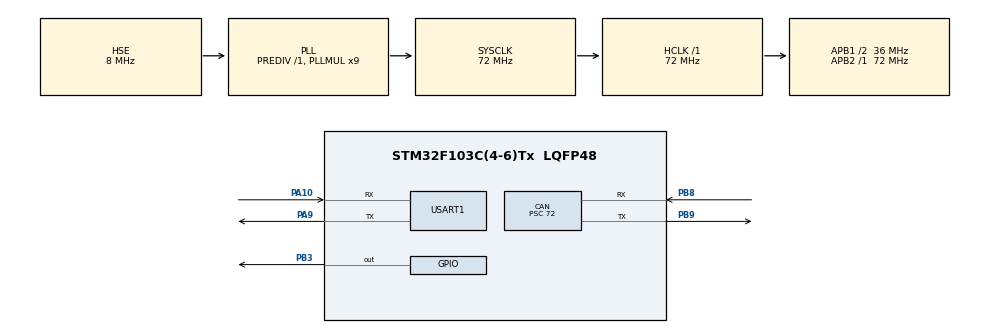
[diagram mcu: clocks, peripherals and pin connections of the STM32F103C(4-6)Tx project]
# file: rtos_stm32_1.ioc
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CAN.BS1=CAN_BS1_2TQ
CAN.CalculateBaudRate=125000
CAN.CalculateTimeBit=8000
CAN.CalculateTimeQuantum=2000.0
CAN.Prescaler=72
FREERTOS.Tasks01=uartTask,0,128,Task_UART_Receive,Default,NULL,Dynamic,NULL,NULL;canTask,0,128,Task_CAN_Send,Default,NULL,Dynamic,NULL,NULL;relay1Task,0,128,Task_Relay1_Control,Default,NULL,Dynamic,NULL,NULL
FREERTOS.configUSE_NEWLIB_REENTRANT=1
Mcu.Family=STM32F1
Mcu.Name=STM32F103C(4-6)Tx
Mcu.Package=LQFP48
NVIC.CAN1_RX1_IRQn=true\:5\:0\:false\:false\:true\:true\:true\:true\:true
NVIC.PriorityGroup=NVIC_PRIORITYGROUP_4
NVIC.TIM3_IRQn=true\:15\:0\:false\:false\:true\:false\:false\:true\:true
NVIC.TimeBase=TIM3_IRQn
NVIC.TimeBaseIP=TIM3
PA10.Mode=Asynchronous
PA10.Signal=USART1_RX
PA13.Mode=Serial_Wire
PA13.Signal=SYS_JTMS-SWDIO
PA14.Mode=Serial_Wire
PA14.Signal=SYS_JTCK-SWCLK
PA9.Mode=Asynchronous
PA9.Signal=USART1_TX
PB3.Signal=GPIO_Output
PB8.Mode=CAN_Activate
PB8.Signal=CAN_RX
PB9.Mode=CAN_Activate
PB9.Signal=CAN_TX
PD0-OSC_IN.Mode=HSE-External-Oscillator
PD0-OSC_IN.Signal=RCC_OSC_IN
PD1-OSC_OUT.Mode=HSE-External-Oscillator
PD1-OSC_OUT.Signal=RCC_OSC_OUT
ProjectManager.HeapSize=0x200
ProjectManager.StackSize=0x400
ProjectManager.TargetToolchain=STM32CubeIDE
RCC.AHBFreq_Value=72000000
RCC.APB1CLKDivider=RCC_HCLK_DIV2
RCC.APB1Freq_Value=36000000
RCC.APB1TimFreq_Value=72000000
RCC.APB2Freq_Value=72000000
RCC.APB2TimFreq_Value=72000000
RCC.HCLKFreq_Value=72000000
RCC.PLLMUL=RCC_PLL_MUL9
RCC.PLLSourceVirtual=RCC_PLLSOURCE_HSE
RCC.SYSCLKFreq_VALUE=72000000
RCC.SYSCLKSource=RCC_SYSCLKSOURCE_PLLCLK
RCC.USBFreq_Value=72000000
USART1.VirtualMode=VM_ASYNC
VP_FREERTOS_VS_CMSIS_V1.Mode=CMSIS_V1
VP_SYS_VS_tim3.Mode=TIM3
board=custom

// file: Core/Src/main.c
/* USER CODE BEGIN Header */
/**
  ******************************************************************************
  * @file           : main.c
  * @brief          : Main program body
  ******************************************************************************
  * @attention
  *
  * Copyright (c) 2025 STMicroelectronics.
  * All rights reserved.
  *
  * This software is licensed under terms that can be found in the LICENSE file
  * in the root directory of this software component.
  * If no LICENSE file comes with this software, it is provided AS-IS.
  *
  ******************************************************************************
  */
/* USER CODE END Header */
#include "main.h"
#include "cmsis_os.h"
#include <string.h>

CAN_HandleTypeDef hcan;

UART_HandleTypeDef huart1;

osThreadId uartTaskHandle;
osThreadId canTaskHandle;
osThreadId relay1TaskHandle;
QueueHandle_t uartQueue, canQueue;

void SystemClock_Config(void);
static void MX_GPIO_Init(void);
static void MX_CAN_Init(void);
static void MX_USART1_UART_Init(void);
void Task_UART_Receive(void const * argument);
void Task_CAN_Send(void const * argument);
void Task_Relay1_Control(void const * argument);

int main(void)
{

  /* MCU Configuration--------------------------------------------------------*/

  /* Reset of all peripherals, Initializes the Flash interface and the Systick. */
  HAL_Init();

  /* Configure the system clock */
  SystemClock_Config();

  /* Initialize all configured peripherals */
  MX_GPIO_Init();
  MX_CAN_Init();
  MX_USART1_UART_Init();
  /* USER CODE BEGIN 2 */
  HAL_GPIO_WritePin(GPIOB, GPIO_PIN_3, GPIO_PIN_SET);
  uartQueue = xQueueCreate(10, sizeof(uint8_t));
        canQueue = xQueueCreate(10, sizeof(uint8_t));
  /* USER CODE END 2 */

  /* Create the thread(s) */
  /* definition and creation of uartTask */
  osThreadDef(uartTask, Task_UART_Receive, osPriorityNormal, 0, 128);
  uartTaskHandle = osThreadCreate(osThread(uartTask), NULL);

  /* definition and creation of canTask */
  osThreadDef(canTask, Task_CAN_Send, osPriorityNormal, 0, 128);
  canTaskHandle = osThreadCreate(osThread(canTask), NULL);

  /* definition and creation of relay1Task */
  osThreadDef(relay1Task, Task_Relay1_Control, osPriorityNormal, 0, 128);
  relay1TaskHandle = osThreadCreate(osThread(relay1Task), NULL);

  /* Start scheduler */
  osKernelStart();

  /* We should never get here as control is now taken by the scheduler */

  /* Infinite loop */
  while (1)
  {

  }
}

void SystemClock_Config(void)
{
  RCC_OscInitTypeDef RCC_OscInitStruct = {0};
  RCC_ClkInitTypeDef RCC_ClkInitStruct = {0};

  /** Initializes the RCC Oscillators according to the specified parameters
  * in the RCC_OscInitTypeDef structure.
  */
  RCC_OscInitStruct.OscillatorType = RCC_OSCILLATORTYPE_HSE;
  RCC_OscInitStruct.HSEState = RCC_HSE_ON;
  RCC_OscInitStruct.HSEPredivValue = RCC_HSE_PREDIV_DIV1;
  RCC_OscInitStruct.HSIState = RCC_HSI_ON;
  RCC_OscInitStruct.PLL.PLLState = RCC_PLL_ON;
  RCC_OscInitStruct.PLL.PLLSource = RCC_PLLSOURCE_HSE;
  RCC_OscInitStruct.PLL.PLLMUL = RCC_PLL_MUL9;
  if (HAL_RCC_OscConfig(&RCC_OscInitStruct) != HAL_OK)
  {
    Error_Handler();
  }

  /** Initializes the CPU, AHB and APB buses clocks
  */
  RCC_ClkInitStruct.ClockType = RCC_CLOCKTYPE_HCLK|RCC_CLOCKTYPE_SYSCLK
                              |RCC_CLOCKTYPE_PCLK1|RCC_CLOCKTYPE_PCLK2;
  RCC_ClkInitStruct.SYSCLKSource = RCC_SYSCLKSOURCE_PLLCLK;
  RCC_ClkInitStruct.AHBCLKDivider = RCC_SYSCLK_DIV1;
  RCC_ClkInitStruct.APB1CLKDivider = RCC_HCLK_DIV2;
  RCC_ClkInitStruct.APB2CLKDivider = RCC_HCLK_DIV1;

  if (HAL_RCC_ClockConfig(&RCC_ClkInitStruct, FLASH_LATENCY_2) != HAL_OK)
  {
    Error_Handler();
  }
}

static void MX_CAN_Init(void)
{

  hcan.Instance = CAN1;
  hcan.Init.Prescaler = 72;
  hcan.Init.Mode = CAN_MODE_NORMAL;
  hcan.Init.SyncJumpWidth = CAN_SJW_1TQ;
  hcan.Init.TimeSeg1 = CAN_BS1_2TQ;
  hcan.Init.TimeSeg2 = CAN_BS2_1TQ;
  hcan.Init.TimeTriggeredMode = DISABLE;
  hcan.Init.AutoBusOff = DISABLE;
  hcan.Init.AutoWakeUp = DISABLE;
  hcan.Init.AutoRetransmission = DISABLE;
  hcan.Init.ReceiveFifoLocked = DISABLE;
  hcan.Init.TransmitFifoPriority = DISABLE;
  if (HAL_CAN_Init(&hcan) != HAL_OK)
  {
    Error_Handler();
  }

}

static void MX_USART1_UART_Init(void)
{

  huart1.Instance = USART1;
  huart1.Init.BaudRate = 115200;
  huart1.Init.WordLength = UART_WORDLENGTH_8B;
  huart1.Init.StopBits = UART_STOPBITS_1;
  huart1.Init.Parity = UART_PARITY_NONE;
  huart1.Init.Mode = UART_MODE_TX_RX;
  huart1.Init.HwFlowCtl = UART_HWCONTROL_NONE;
  huart1.Init.OverSampling = UART_OVERSAMPLING_16;
  if (HAL_UART_Init(&huart1) != HAL_OK)
  {
    Error_Handler();
  }

}

static void MX_GPIO_Init(void)
{
  GPIO_InitTypeDef GPIO_InitStruct = {0};

  /* GPIO Ports Clock Enable */
  __HAL_RCC_GPIOD_CLK_ENABLE();
  __HAL_RCC_GPIOA_CLK_ENABLE();
  __HAL_RCC_GPIOB_CLK_ENABLE();

  /*Configure GPIO pin Output Level */
  HAL_GPIO_WritePin(GPIOB, GPIO_PIN_3, GPIO_PIN_RESET);

  /*Configure GPIO pin : PB3 */
  GPIO_InitStruct.Pin = GPIO_PIN_3;
  GPIO_InitStruct.Mode = GPIO_MODE_OUTPUT_PP;
  GPIO_InitStruct.Pull = GPIO_NOPULL;
  GPIO_InitStruct.Speed = GPIO_SPEED_FREQ_LOW;
  HAL_GPIO_Init(GPIOB, &GPIO_InitStruct);

}

void Task_UART_Receive(void const * argument)
{
	uint8_t rxData;
		    while (1)
		    {
		        if (HAL_UART_Receive(&huart1, &rxData, 1, HAL_MAX_DELAY) == HAL_OK)
		        {
		            xQueueSend(uartQueue, &rxData, portMAX_DELAY);
		        }
		    }
}

void Task_CAN_Send(void const * argument)
{
	CAN_TxHeaderTypeDef TxHeader;
		    uint8_t TxData[8];
		    uint32_t TxMailbox;
		    uint8_t receivedData;

		    HAL_CAN_Start(&hcan);
		    HAL_CAN_ActivateNotification(&hcan, CAN_IT_RX_FIFO0_MSG_PENDING);

		    TxHeader.StdId = 0x123;
		    TxHeader.ExtId = 0;
		    TxHeader.RTR = CAN_RTR_DATA;
		    TxHeader.IDE = CAN_ID_STD;
		    TxHeader.DLC = 8;
		    TxHeader.TransmitGlobalTime = DISABLE;

		    while (1)
		    {
		        if (xQueueReceive(canQueue, &receivedData, portMAX_DELAY))
		        {
		        	if(receivedData=='3'){
		            memset(TxData, 0, 8);
		            TxData[0] = '1';}
		        	else {memset(TxData, 0, 8);
		            TxData[0] = '2';}
		            HAL_CAN_AddTxMessage(&hcan, &TxHeader, TxData, &TxMailbox);
		        }
		    }
}

void Task_Relay1_Control(void const * argument)
{
	uint8_t receivedData;
		    while (1)
		    {
		        if (xQueueReceive(uartQueue, &receivedData, portMAX_DELAY))
		        {
		            if (receivedData == '1')
		                HAL_GPIO_WritePin(GPIOB, GPIO_PIN_3, GPIO_PIN_SET);
		            else if (receivedData == '2')
		                HAL_GPIO_WritePin(GPIOB, GPIO_PIN_3, GPIO_PIN_RESET);
		            else if (receivedData == '3' || receivedData == '4')
		                xQueueSend(canQueue, &receivedData, portMAX_DELAY);
		        }
		    }
}

void HAL_TIM_PeriodElapsedCallback(TIM_HandleTypeDef *htim)
{
  if (htim->Instance == TIM3) {
    HAL_IncTick();
  }
}

void Error_Handler(void)
{
  __disable_irq();
  while (1)
  {
  }
}
